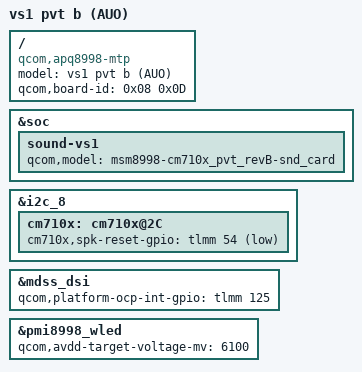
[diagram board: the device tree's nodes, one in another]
/* Copyright (c) 2016, The Linux Foundation. All rights reserved.
 *
 * This program is free software; you can redistribute it and/or modify
 * it under the terms of the GNU General Public License version 2 and
 * only version 2 as published by the Free Software Foundation.
 *
 * This program is distributed in the hope that it will be useful,
 * but WITHOUT ANY WARRANTY; without even the implied warranty of
 * MERCHANTABILITY or FITNESS FOR A PARTICULAR PURPOSE.  See the
 * GNU General Public License for more details.
 */


/dts-v1/;

#include "vs1-dvt.dtsi"

/ {
	model = "vs1 pvt b (AUO)";
	compatible = "qcom,apq8998-mtp", "qcom,apq8998", "qcom,mtp";
	qcom,board-id = <0x08 0x0D>;
};

&soc {
	sound-vs1 {
		qcom,model = "msm8998-cm710x_pvt_revB-snd_card";
	};
};

&i2c_8 {
	cm710x: cm710x@2C {
		cm710x,spk-reset-gpio = <&tlmm 54 1>;
	};
};

&mdss_dsi {
	qcom,platform-ocp-int-gpio = <&tlmm 125 0>;
};

&pmi8998_wled {
	qcom,avdd-target-voltage-mv = <6100>;
};
